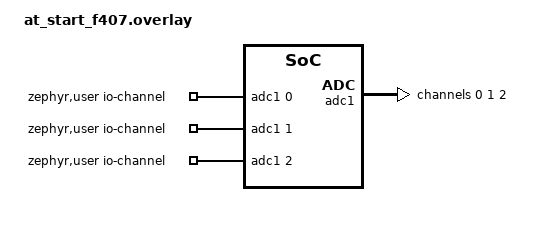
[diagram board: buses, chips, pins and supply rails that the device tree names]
/* Copyright (c) 2021 STMicroelectronics
   SPDX-License-Identifier: Apache-2.0 */

/ {
	zephyr,user {
		/* adjust channel number according to pinmux in board.dts */
		io-channels = <&adc1 0>, <&adc1 1>, <&adc1 2>;
	};
};

/ {
	aliases {
		adc0 = &adc1;
	};
};

&adc1 {
	#address-cells = <1>;
	#size-cells = <0>;
    channel@0 {
		reg = <0>;
		zephyr,gain = "ADC_GAIN_1";
		zephyr,reference = "ADC_REF_INTERNAL";
		zephyr,acquisition-time = <ADC_ACQ_TIME(ADC_ACQ_TIME_TICKS, 240)>;
		zephyr,resolution = <12>;
		zephyr,input-positive = <0>;
	};
	channel@1 {
		reg = <1>;
		zephyr,gain = "ADC_GAIN_1";
		zephyr,reference = "ADC_REF_INTERNAL";
		zephyr,acquisition-time = <ADC_ACQ_TIME(ADC_ACQ_TIME_TICKS, 240)>;
		zephyr,resolution = <12>;
		zephyr,input-positive = <1>;
	};
	channel@2 {
		reg = <2>;
		zephyr,gain = "ADC_GAIN_1";
		zephyr,reference = "ADC_REF_INTERNAL";
		zephyr,acquisition-time = <ADC_ACQ_TIME(ADC_ACQ_TIME_TICKS, 240)>;
		zephyr,resolution = <12>;
		zephyr,input-positive = <2>;
	};
};
